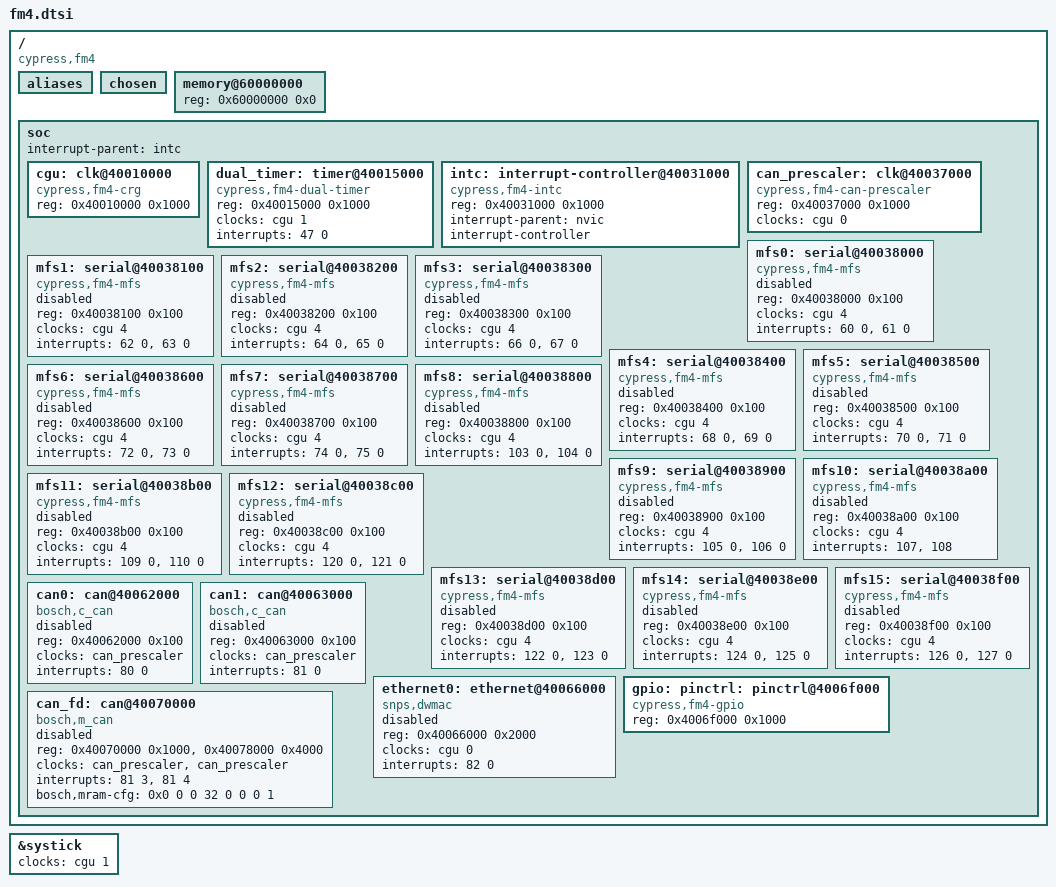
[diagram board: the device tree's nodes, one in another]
/*
 * Device tree for Spansion/Cypress FM4
 *
 * Copyright (c) 2015-2017 Andreas Färber
 *
 * SPDX-License-Identifier: (GPL-2.0+ OR MIT)
 */

#include "armv7-m.dtsi"

/ {
	compatible = "cypress,fm4";
	#address-cells = <1>;
	#size-cells = <1>;

	aliases {
	};

	chosen {
	};

	memory@60000000 {
		device_type = "memory";
		reg = <0x60000000 0x0>;
	};

	soc {
		interrupt-parent = <&intc>;

		cgu: clk@40010000 {
			compatible = "cypress,fm4-crg";
			reg = <0x40010000 0x1000>;
			#clock-cells = <1>;
		};

		dual_timer: timer@40015000 {
			compatible = "cypress,fm4-dual-timer";
			reg = <0x40015000 0x1000>;
			clocks = <&cgu 1>;
			interrupts = <47 0>;
		};

		intc: interrupt-controller@40031000 {
			compatible = "cypress,fm4-intc";
			reg = <0x40031000 0x1000>;
			interrupt-parent = <&nvic>;
			interrupt-controller;
			#interrupt-cells = <2>;
		};

		can_prescaler: clk@40037000 {
			compatible = "cypress,fm4-can-prescaler";
			reg = <0x40037000 0x1000>;
			clocks = <&cgu 0>;
			#clock-cells = <0>;
		};

		mfs0: serial@40038000 {
			compatible = "cypress,fm4-mfs";
			reg = <0x40038000 0x100>;
			clocks = <&cgu 4>;
			interrupts = <60 0>, <61 0>;
			status = "disabled";
		};

		mfs1: serial@40038100 {
			compatible = "cypress,fm4-mfs";
			reg = <0x40038100 0x100>;
			clocks = <&cgu 4>;
			interrupts = <62 0>, <63 0>;
			status = "disabled";
		};

		mfs2: serial@40038200 {
			compatible = "cypress,fm4-mfs";
			reg = <0x40038200 0x100>;
			clocks = <&cgu 4>;
			interrupts = <64 0>, <65 0>;
			status = "disabled";
		};

		mfs3: serial@40038300 {
			compatible = "cypress,fm4-mfs";
			reg = <0x40038300 0x100>;
			clocks = <&cgu 4>;
			interrupts = <66 0>, <67 0>;
			status = "disabled";
		};

		mfs4: serial@40038400 {
			compatible = "cypress,fm4-mfs";
			reg = <0x40038400 0x100>;
			clocks = <&cgu 4>;
			interrupts = <68 0>, <69 0>;
			status = "disabled";
		};

		mfs5: serial@40038500 {
			compatible = "cypress,fm4-mfs";
			reg = <0x40038500 0x100>;
			clocks = <&cgu 4>;
			interrupts = <70 0>, <71 0>;
			status = "disabled";
		};

		mfs6: serial@40038600 {
			compatible = "cypress,fm4-mfs";
			reg = <0x40038600 0x100>;
			clocks = <&cgu 4>;
			interrupts = <72 0>, <73 0>;
			status = "disabled";
		};

		mfs7: serial@40038700 {
			compatible = "cypress,fm4-mfs";
			reg = <0x40038700 0x100>;
			clocks = <&cgu 4>;
			interrupts = <74 0>, <75 0>;
			status = "disabled";
		};

		mfs8: serial@40038800 {
			compatible = "cypress,fm4-mfs";
			reg = <0x40038800 0x100>;
			clocks = <&cgu 4>;
			interrupts = <103 0>, <104 0>;
			status = "disabled";
		};

		mfs9: serial@40038900 {
			compatible = "cypress,fm4-mfs";
			reg = <0x40038900 0x100>;
			clocks = <&cgu 4>;
			interrupts = <105 0>, <106 0>;
			status = "disabled";
		};

		mfs10: serial@40038a00 {
			compatible = "cypress,fm4-mfs";
			reg = <0x40038a00 0x100>;
			clocks = <&cgu 4>;
			interrupts = <107>, <108>;
			status = "disabled";
		};

		mfs11: serial@40038b00 {
			compatible = "cypress,fm4-mfs";
			reg = <0x40038b00 0x100>;
			clocks = <&cgu 4>;
			interrupts = <109 0>, <110 0>;
			status = "disabled";
		};

		mfs12: serial@40038c00 {
			compatible = "cypress,fm4-mfs";
			reg = <0x40038c00 0x100>;
			clocks = <&cgu 4>;
			interrupts = <120 0>, <121 0>;
			status = "disabled";
		};

		mfs13: serial@40038d00 {
			compatible = "cypress,fm4-mfs";
			reg = <0x40038d00 0x100>;
			clocks = <&cgu 4>;
			interrupts = <122 0>, <123 0>;
			status = "disabled";
		};

		mfs14: serial@40038e00 {
			compatible = "cypress,fm4-mfs";
			reg = <0x40038e00 0x100>;
			clocks = <&cgu 4>;
			interrupts = <124 0>, <125 0>;
			status = "disabled";
		};

		mfs15: serial@40038f00 {
			compatible = "cypress,fm4-mfs";
			reg = <0x40038f00 0x100>;
			clocks = <&cgu 4>;
			interrupts = <126 0>, <127 0>;
			status = "disabled";
		};

		can0: can@40062000 {
			compatible = "bosch,c_can";
			reg = <0x40062000 0x100>;
			clocks = <&can_prescaler>;
			interrupts = <80 0>;
			status = "disabled";
		};

		can1: can@40063000 {
			compatible = "bosch,c_can";
			reg = <0x40063000 0x100>;
			clocks = <&can_prescaler>;
			interrupts = <81 0>;
			status = "disabled";
		};

		ethernet0: ethernet@40066000 {
			compatible = "snps,dwmac";
			reg = <0x40066000 0x2000>;
			clocks = <&cgu 0>;
			clock-names = "stmmaceth";
			interrupts = <82 0>;
			interrupt-names = "macirq";
			status = "disabled";
		};

		gpio: pinctrl: pinctrl@4006f000 {
			compatible = "cypress,fm4-gpio";
			reg = <0x4006f000 0x1000>;
			#gpio-cells = <3>;
		};

		can_fd: can@40070000 {
			compatible = "bosch,m_can";
			reg = <0x40070000 0x1000>, <0x40078000 0x4000>;
			reg-names = "m_can", "message_ram";
			clocks = <&can_prescaler>, <&can_prescaler>;
			clock-names = "hclk", "cclk";
			interrupts = <81 3>, <81 4>;
			interrupt-names = "int0", "int1";
			bosch,mram-cfg = <0x0 0 0 32 0 0 0 1>;
			status = "disabled";
		};
	};
};

&systick {
	status = "okay";
	clocks = <&cgu 1>;
};
